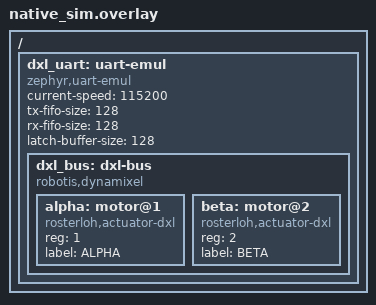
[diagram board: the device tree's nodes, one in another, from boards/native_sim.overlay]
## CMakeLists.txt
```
# Copyright (c) 2024 Richard Osterloh <richard.osterloh@gmail.com>
# SPDX-License-Identifier: Apache-2.0
cmake_minimum_required(VERSION 3.20.0)

find_package(Zephyr REQUIRED HINTS $ENV{ZEPHYR_BASE})
project(test_dynamixel)

target_sources(app PRIVATE
    src/main.c
    src/fake_servo.c
    src/fake_bus.c
    src/test_protocol.c
    src/test_tables.c
    src/test_motors.c
    src/test_sync.c
    src/test_bulk.c
)

zephyr_include_directories(./src)
zephyr_include_directories(${ZEPHYR_DRIVERS_REPO_ROOT}/drivers/dynamixel)
```

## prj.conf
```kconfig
# tests/drivers/dynamixel/prj.conf
CONFIG_LOG=y
CONFIG_ZTEST=y
CONFIG_SERIAL=y
CONFIG_UART_INTERRUPT_DRIVEN=y
CONFIG_EMUL=y
CONFIG_UART_EMUL=y
CONFIG_DYNAMIXEL=y
CONFIG_DYNAMIXEL_LOG_LEVEL_DBG=y
# Higher tick resolution so that µs-level timeouts (rxwait_to, packet_timer,
# SYNC/BULK slot gaps) quantise accurately on native_sim's 1 MHz HW clock.
CONFIG_SYS_CLOCK_TICKS_PER_SEC=10000
```

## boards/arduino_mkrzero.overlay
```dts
/*
 * Copyright (c) 2024 Richard Osterloh <richard.osterloh@gmail.com>
 *
 * SPDX-License-Identifier: Apache-2.0
 */
 
 &sercom5 {
	status = "okay";
	current-speed = <115200>;

	dynamixel0 {
		status = "okay";
		compatible = "robotis,dynamixel";
		tx-en-gpios = <&arduino_mkr_header 21 GPIO_ACTIVE_LOW>; // A6

		test_motor {
			id = <1>;
			label = "TEST";
		};
	};
};
```

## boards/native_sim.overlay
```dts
/*
 * Copyright (c) 2026 Richard Osterloh <richard.osterloh@gmail.com>
 *
 * SPDX-License-Identifier: Apache-2.0
 */

/ {
	dxl_uart: uart-emul {
		compatible = "zephyr,uart-emul";
		current-speed = <115200>;
		tx-fifo-size = <128>;
		rx-fifo-size = <128>;
		latch-buffer-size = <128>;
		status = "okay";

		dxl_bus: dxl-bus {
			status = "okay";
			compatible = "robotis,dynamixel";
			#address-cells = <1>;
			#size-cells = <0>;

			alpha: motor@1 {
				compatible = "rosterloh,actuator-dxl";
				reg = <1>;
				label = "ALPHA";
			};

			beta: motor@2 {
				compatible = "rosterloh,actuator-dxl";
				reg = <2>;
				label = "BETA";
			};
		};
	};
};
```

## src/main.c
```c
/*
 * Copyright (c) 2026 Richard Osterloh <richard.osterloh@gmail.com>
 *
 * SPDX-License-Identifier: Apache-2.0
 */

#include <zephyr/ztest.h>

ZTEST_SUITE(dynamixel_tables, NULL, NULL, NULL, NULL, NULL);
ZTEST_SUITE(dynamixel_motors, NULL, NULL, NULL, NULL, NULL);
```

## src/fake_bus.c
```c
/*
 * Copyright (c) 2026 Richard Osterloh <richard.osterloh@gmail.com>
 *
 * SPDX-License-Identifier: Apache-2.0
 */

#include "fake_bus.h"

#include <string.h>
#include <zephyr/sys/byteorder.h>
#include <zephyr/drivers/serial/uart_emul.h>

#include <zephyr/logging/log.h>
LOG_MODULE_REGISTER(fake_bus, LOG_LEVEL_INF);

#define DXL_BROADCAST_ID 0xFE
#define INST_SYNC_READ   0x82
#define INST_BULK_READ   0x92
#define INST_SYNC_WRITE  0x83
#define INST_BULK_WRITE  0x93

/* Forward decl — implemented later in the SYNC/BULK tasks. */
static void inject_work_fn(struct k_work *w);

struct fake_servo *fake_bus_get(struct fake_bus *bus, uint8_t id)
{
	for (size_t i = 0; i < bus->n; i++) {
		if (bus->srv[i].id == id) {
			return &bus->srv[i];
		}
	}
	return NULL;
}

/* SYNC_WRITE param layout (after instruction byte):
 *   addr_le16 ‖ data_len_le16 ‖ {id, data[L]} × N
 * pkt[8..9]   = addr,
 * pkt[10..11] = data_len,
 * pkt[12..]   = repeating (id, data[L]).
 */
static void dispatch_sync_write(struct fake_bus *bus, const uint8_t *pkt, size_t len)
{
	if (len < 14) {
		return; /* need at least addr + len + crc */
	}
	uint16_t addr = sys_get_le16(&pkt[8]);
	uint16_t data_len = sys_get_le16(&pkt[10]);
	const uint8_t *p = &pkt[12];
	const uint8_t *end = &pkt[len - 2]; /* before CRC */

	while (p + 1 + data_len <= end) {
		uint8_t id = p[0];
		struct fake_servo *s = fake_bus_get(bus, id);
		if (s != NULL && addr + data_len <= FAKE_SERVO_RAM_SIZE) {
			memcpy(&s->control_ram[addr], &p[1], data_len);
			s->last_addr = addr;
			s->last_length = data_len;
		}
		p += 1 + data_len;
	}
}

/* BULK_WRITE param layout (after instruction byte):
 *   {id, addr_le16, len_le16, data[L]} × N
 * pkt[8..]    = repeating per-entry blocks.
 */
static void dispatch_bulk_write(struct fake_bus *bus, const uint8_t *pkt, size_t len)
{
	if (len < 10) {
		return;
	}
	const uint8_t *p = &pkt[8];
	const uint8_t *end = &pkt[len - 2]; /* before CRC */

	while (p + 5 <= end) {
		uint8_t id = p[0];
		uint16_t addr = sys_get_le16(&p[1]);
		uint16_t data_len = sys_get_le16(&p[3]);
		if (p + 5 + data_len > end) {
			break;
		}
		struct fake_servo *s = fake_bus_get(bus, id);
		if (s != NULL && addr + data_len <= FAKE_SERVO_RAM_SIZE) {
			memcpy(&s->control_ram[addr], &p[5], data_len);
			s->last_addr = addr;
			s->last_length = data_len;
		}
		p += 5 + data_len;
	}
}

/* Helper: directly emit a status reply for one fake. Mirrors fake_servo's
 * own send_status path but is reachable from outside the per-fake module.
 *
 * Implementation: reuses fake_servo_handle_packet by feeding it a synthetic
 * READ instruction packet for that servo. This way fake_servo's existing
 * drop_response / corrupt_crc / error_byte knobs apply automatically.
 */
static void emit_status_via_synthetic_read(struct fake_servo *s, uint16_t addr, uint16_t length)
{
	uint8_t synth[14];
	uint16_t length_field = 1 /* inst */ + 4 /* params */ + 2 /* crc */;

	synth[0] = 0xFF;
	synth[1] = 0xFF;
	synth[2] = 0xFD;
	synth[3] = 0x00;
	synth[4] = s->id;
	sys_put_le16(length_field, &synth[5]);
	synth[7] = 0x02; /* INST_READ */
	sys_put_le16(addr, &synth[8]);
	sys_put_le16(length, &synth[10]);
	/* CRC bytes left zero — fake_servo_handle_packet doesn't validate the
	 * inbound CRC, only header + instruction. The bytes at &synth[12] are
	 * "CRC", but handle_packet treats pkt[8..11] as params and ignores
	 * trailing bytes for READ.
	 */

	fake_servo_handle_packet(s, synth, sizeof(synth));
}

/* BULK_READ param layout (after instruction byte):
 *   {id, addr_le16, len_le16} × N
 */
static void dispatch_bulk_read(struct fake_bus *bus, const uint8_t *pkt, size_t len)
{
	if (len < 10) {
		return;
	}
	const uint8_t *p = &pkt[8];
	const uint8_t *end = &pkt[len - 2];
	size_t entries = 0;

	bus->pending_active = true;
	bus->pending_is_bulk = true;
	bus->pending_idx = 0;
	bus->prev_dropped = false;

	while (p + 5 <= end && entries < FAKE_BUS_MAX_SERVOS) {
		bus->pending_ids[entries] = p[0];
		bus->pending_addrs[entries] = sys_get_le16(&p[1]);
		bus->pending_lens[entries] = sys_get_le16(&p[3]);
		entries++;
		p += 5;
	}

	if (entries == 0) {
		bus->pending_active = false;
		return;
	}

	bus->pending_n = entries;
	k_work_reschedule(&bus->inject_work, K_NO_WAIT);
}

/* SYNC_READ param layout (after instruction byte):
 *   addr_le16 ‖ data_len_le16 ‖ id[0..n-1]
 */
static void dispatch_sync_read(struct fake_bus *bus, const uint8_t *pkt, size_t len)
{
	if (len < 14) {
		return;
	}
	uint16_t addr = sys_get_le16(&pkt[8]);
	uint16_t data_len = sys_get_le16(&pkt[10]);
	const uint8_t *id_list = &pkt[12];
	const uint8_t *end = &pkt[len - 2]; /* before CRC */
	size_t n = (size_t)(end - id_list);

	if (n == 0 || n > FAKE_BUS_MAX_SERVOS) {
		return;
	}

	bus->pending_active = true;
	bus->pending_is_bulk = false;
	bus->pending_addr_uniform = addr;
	bus->pending_len_uniform = data_len;
	bus->pending_n = n;
	bus->pending_idx = 0;
	bus->prev_dropped = false;
	for (size_t i = 0; i < n; i++) {
		bus->pending_ids[i] = id_list[i];
	}

	/* Kick off the first injection at K_NO_WAIT so it runs after the test
	 * thread has returned from dxl_sync_read_*'s TX call and entered the
	 * first k_sem_take. K_NO_WAIT is fine because the work item runs on the
	 * system workqueue which can't pre-empt the test thread mid-sem-take.
	 */
	k_work_reschedule(&bus->inject_work, K_NO_WAIT);
}

static void dispatch_single_target(struct fake_bus *bus, const uint8_t *pkt, size_t len)
{
	uint8_t target_id = pkt[4];

	if (target_id == DXL_BROADCAST_ID) {
		/* Broadcast PING/READ/WRITE — out of scope for Task 4; later tasks handle
		 * SYNC/BULK broadcasts which carry their own targeting in params.
		 */
		return;
	}

	struct fake_servo *s = fake_bus_get(bus, target_id);
	if (s != NULL) {
		fake_servo_handle_packet(s, pkt, len);
	}
}

static void tx_data_ready_cb(const struct device *dev, size_t size, void *user_data)
{
	struct fake_bus *bus = user_data;
	uint8_t buf[FAKE_SERVO_LAST_TX_SIZE * 2]; /* large enough for any single-shot frame */
	uint32_t got;

	if (size > sizeof(buf)) {
		size = sizeof(buf);
	}
	got = uart_emul_get_tx_data(dev, buf, size);
	if (got < 10) {
		return; /* malformed: too short for header+id+len+inst+crc */
	}

	/* Capture in every fake's last_tx/last_instruction so test code can assert
	 * on them regardless of which servo was addressed.
	 */
	for (size_t i = 0; i < bus->n; i++) {
		struct fake_servo *s = &bus->srv[i];
		s->last_tx_len = MIN(got, sizeof(s->last_tx));
		memcpy(s->last_tx, buf, s->last_tx_len);
		s->last_instruction = buf[7];
	}

	uint8_t inst = buf[7];

	switch (inst) {
	case INST_SYNC_READ:
		dispatch_sync_read(bus, buf, got);
		break;
	case INST_SYNC_WRITE:
		dispatch_sync_write(bus, buf, got);
		break;
	case INST_BULK_READ:
		dispatch_bulk_read(bus, buf, got);
		break;
	case INST_BULK_WRITE:
		dispatch_bulk_write(bus, buf, got);
		break;
	default:
		dispatch_single_target(bus, buf, got);
		break;
	}
}

void fake_bus_init(struct fake_bus *bus, const uint8_t ids[], size_t n)
{
	memset(bus, 0, sizeof(*bus));
	bus->n = MIN(n, (size_t)FAKE_BUS_MAX_SERVOS);
	for (size_t i = 0; i < bus->n; i++) {
		fake_servo_init(&bus->srv[i], ids[i]);
	}
	k_work_init_delayable(&bus->inject_work, inject_work_fn);
}

void fake_bus_attach(struct fake_bus *bus, const struct device *uart)
{
	bus->uart = uart;
	for (size_t i = 0; i < bus->n; i++) {
		bus->srv[i].uart = uart;
	}
	uart_emul_callback_tx_data_ready_set(uart, tx_data_ready_cb, bus);
}

void fake_bus_set_u8(struct fake_bus *bus, uint8_t id, uint16_t addr, uint8_t value)
{
	struct fake_servo *s = fake_bus_get(bus, id);
	if (s != NULL) {
		fake_servo_set_u8(s, addr, value);
	}
}

void fake_bus_set_u16(struct fake_bus *bus, uint8_t id, uint16_t addr, uint16_t value)
{
	struct fake_servo *s = fake_bus_get(bus, id);
	if (s != NULL) {
		fake_servo_set_u16(s, addr, value);
	}
}

void fake_bus_set_u32(struct fake_bus *bus, uint8_t id, uint16_t addr, uint32_t value)
{
	struct fake_servo *s = fake_bus_get(bus, id);
	if (s != NULL) {
		fake_servo_set_u32(s, addr, value);
	}
}

static void inject_work_fn(struct k_work *w)
{
	struct k_work_delayable *dw = k_work_delayable_from_work(w);
	struct fake_bus *bus = CONTAINER_OF(dw, struct fake_bus, inject_work);

	if (!bus->pending_active || bus->pending_idx >= bus->pending_n) {
		bus->pending_active = false;
		return;
	}

	uint8_t id = bus->pending_ids[bus->pending_idx];
	uint16_t addr = bus->pending_is_bulk ? bus->pending_addrs[bus->pending_idx]
					     : bus->pending_addr_uniform;
	uint16_t length = bus->pending_is_bulk ? bus->pending_lens[bus->pending_idx]
					       : bus->pending_len_uniform;

	struct fake_servo *s = fake_bus_get(bus, id);
	bool dropped = (s == NULL) || s->drop_response;

	if (s != NULL) {
		emit_status_via_synthetic_read(s, addr, length);
	}

	bus->pending_idx++;
	bus->prev_dropped = dropped;

	if (bus->pending_idx < bus->pending_n) {
		uint32_t gap = bus->prev_dropped ? FAKE_BUS_DROP_GAP_US : FAKE_BUS_SLOT_GAP_US;
		k_work_reschedule(&bus->inject_work, K_USEC(gap));
	} else {
		bus->pending_active = false;
	}
}
```

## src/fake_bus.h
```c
/*
 * Copyright (c) 2026 Richard Osterloh <richard.osterloh@gmail.com>
 *
 * SPDX-License-Identifier: Apache-2.0
 */

#ifndef TEST_FAKE_BUS_H_
#define TEST_FAKE_BUS_H_

#include <stdbool.h>
#include <stdint.h>
#include <stddef.h>
#include <zephyr/device.h>
#include <zephyr/kernel.h>
#include <drivers/dynamixel.h>

#include "fake_servo.h"

#define FAKE_BUS_MAX_SERVOS 4

/* Inter-packet timing for sync/bulk read injection.
 *
 * SLOT_GAP_US: gap between consecutive injected status packets in the
 *   happy-path case. Must exceed the driver's inter-frame packet_timeout
 *   (~1003 us at 115200 baud) so the packet_timer fires between frames.
 *
 * DROP_GAP_US: gap when the previous slot was a drop. Must satisfy
 *   (rxwait_to - SLOT_GAP) < DROP_GAP < (2*rxwait_to - packet_timer):
 *   - lower bound prevents the next inject arriving while the dropped slot
 *     k_sem_take is still active (would corrupt expected_id matching);
 *   - upper bound ensures the next inject arrives inside the next slot's
 *     k_sem_take window with margin for the inter-frame packet_timer.
 *   With rxwait_to = 10 ms, the safe range is roughly 7..14 ms; 12 ms gives
 *   ~3 ms margin on both sides.
 */
#define FAKE_BUS_SLOT_GAP_US 5000U
#define FAKE_BUS_DROP_GAP_US 12000U

struct fake_bus {
	struct fake_servo srv[FAKE_BUS_MAX_SERVOS];
	size_t n;
	const struct device *uart;

	/* Pending response queue (set by tx dispatcher when SYNC/BULK_READ seen). */
	bool pending_active;
	bool pending_is_bulk;
	uint8_t pending_ids[FAKE_BUS_MAX_SERVOS];
	uint16_t pending_addr_uniform;               /* sync-read only */
	uint16_t pending_len_uniform;                /* sync-read only */
	uint16_t pending_addrs[FAKE_BUS_MAX_SERVOS]; /* bulk-read only */
	uint16_t pending_lens[FAKE_BUS_MAX_SERVOS];  /* bulk-read only */
	size_t pending_n;
	size_t pending_idx;
	bool prev_dropped;

	struct k_work_delayable inject_work;
};

void fake_bus_init(struct fake_bus *bus, const uint8_t ids[], size_t n);
void fake_bus_attach(struct fake_bus *bus, const struct device *uart);

struct fake_servo *fake_bus_get(struct fake_bus *bus, uint8_t id);

/* Convenience wrappers for pre-loading register state per servo by id. */
void fake_bus_set_u8(struct fake_bus *bus, uint8_t id, uint16_t addr, uint8_t value);
void fake_bus_set_u16(struct fake_bus *bus, uint8_t id, uint16_t addr, uint16_t value);
void fake_bus_set_u32(struct fake_bus *bus, uint8_t id, uint16_t addr, uint32_t value);

#endif /* TEST_FAKE_BUS_H_ */
```

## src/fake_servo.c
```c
/*
 * Copyright (c) 2026 Richard Osterloh <richard.osterloh@gmail.com>
 *
 * SPDX-License-Identifier: Apache-2.0
 */

#include "fake_servo.h"

#include <string.h>
#include <zephyr/sys/byteorder.h>
#include <zephyr/sys/crc.h>
#include <zephyr/drivers/serial/uart_emul.h>

#include <zephyr/logging/log.h>
LOG_MODULE_REGISTER(fake_servo, LOG_LEVEL_INF);

#define DXL_HDR0 0xFF
#define DXL_HDR1 0xFF
#define DXL_HDR2 0xFD
#define DXL_RSV  0x00

#define INST_PING   0x01
#define INST_READ   0x02
#define INST_WRITE  0x03
#define INST_REBOOT 0x08
#define INST_STATUS 0x55

#define CRC_POLY 0x8005
#define CRC_SEED 0x0000

/* Protocol 2.0 byte stuffing from offset 8: an extra 0xFD follows every FF FF FD. */
static bool stuff_point(const uint8_t *buf, size_t i)
{
	return i >= 10 && buf[i - 2] == 0xFF && buf[i - 1] == 0xFF && buf[i] == 0xFD;
}

/* Stuff buf[8..len) in place; returns the new length. */
static size_t stuff(uint8_t *buf, size_t len, size_t cap)
{
	for (size_t i = 8; i < len; i++) {
		if (stuff_point(buf, i) && len < cap) {
			memmove(&buf[i + 2], &buf[i + 1], len - i - 1);
			buf[++i] = 0xFD;
			len++;
		}
	}
	return len;
}

/* Undo stuff() on buf[8..len); returns the new length. */
static size_t unstuff(uint8_t *buf, size_t len)
{
	size_t out = 8;

	for (size_t i = 8; i < len; i++) {
		if (stuff_point(buf, i - 1) && buf[i] == 0xFD) {
			continue;
		}
		buf[out++] = buf[i];
	}
	return out;
}

static void send_status(struct fake_servo *s, uint8_t error, const uint8_t *params,
			uint16_t params_len)
{
	uint8_t buf[FAKE_SERVO_STATUS_BUF_SIZE];
	uint16_t length = params_len + 1 /* error */ + 2 /* crc */ + 1 /* instruction */;
	uint16_t total = length + 7;
	uint16_t crc;

	if (s->drop_response) {
		return;
	}

	buf[0] = DXL_HDR0;
	buf[1] = DXL_HDR1;
	buf[2] = DXL_HDR2;
	buf[3] = DXL_RSV;
	buf[4] = s->id;
	sys_put_le16(length, &buf[5]);
	buf[7] = INST_STATUS;
	buf[8] = error;
	if (params_len > 0) {
		memcpy(&buf[9], params, params_len);
	}
	total = stuff(buf, total - 2, sizeof(buf) - 2) + 2;
	sys_put_le16(total - 7, &buf[5]);
	crc = crc16(CRC_POLY, CRC_SEED, buf, total - 2);
	if (s->corrupt_crc) {
		crc ^= 0x0001;
	}
	sys_put_le16(crc, &buf[total - 2]);
	if (s->corrupt_length) {
		sys_put_le16(0xFFFF, &buf[5]);
	}

	uart_emul_put_rx_data(s->uart, buf, total);
}

void fake_servo_handle_packet(struct fake_servo *s, const uint8_t *pkt, size_t len)
{
	uint8_t id;
	uint16_t length;
	uint8_t inst;

	if (len < 10) {
		return;
	}
	if (pkt[0] != DXL_HDR0 || pkt[1] != DXL_HDR1 || pkt[2] != DXL_HDR2) {
		return;
	}
	/* Capture the wire bytes for assertions, then parse the unstuffed frame. */
	s->last_tx_len = MIN(len, sizeof(s->last_tx));
	memcpy(s->last_tx, pkt, s->last_tx_len);

	uint8_t raw[FAKE_SERVO_LAST_TX_SIZE];

	memcpy(raw, pkt, s->last_tx_len);
	len = unstuff(raw, s->last_tx_len - 2) + 2;
	pkt = raw;

	id = pkt[4];
	length = len - 7;
	inst = pkt[7];
	s->last_instruction = inst;

	if (id != s->id && !s->answer_any_id) {
		return; /* not addressed to this servo */
	}

	switch (inst) {
	case INST_PING:
		send_status(s, s->error_byte, NULL, 0);
		break;
	case INST_READ: {
		if (len < 14) {
			return; /* malformed: READ needs 4 param bytes */
		}
		uint16_t addr = sys_get_le16(&pkt[8]);
		uint16_t rlen = sys_get_le16(&pkt[10]);
		s->last_addr = addr;
		s->last_length = rlen;
		if (addr + rlen <= FAKE_SERVO_RAM_SIZE) {
			send_status(s, s->error_byte, &s->control_ram[addr], rlen);
		} else {
			send_status(s, s->error_byte, NULL, 0);
		}
		break;
	}
	case INST_WRITE: {
		if (len < 12) {
			return; /* malformed: WRITE needs at least 2 addr bytes */
		}
		uint16_t addr = sys_get_le16(&pkt[8]);
		uint16_t params = length - 5; /* length covers ic + 2 addr + params + 2 crc */
		s->last_addr = addr;
		s->last_length = params;
		if (addr + params <= FAKE_SERVO_RAM_SIZE) {
			memcpy(&s->control_ram[addr], &pkt[10], params);
		}
		send_status(s, s->error_byte, NULL, 0);
		break;
	}
	case INST_REBOOT:
		send_status(s, s->error_byte, NULL, 0);
		break;
	default:
		break;
	}
}

static void tx_data_ready_cb(const struct device *dev, size_t size, void *user_data)
{
	struct fake_servo *s = user_data;
	uint8_t buf[FAKE_SERVO_LAST_TX_SIZE];
	uint32_t got;

	if (size > sizeof(buf)) {
		size = sizeof(buf);
	}
	got = uart_emul_get_tx_data(dev, buf, size);
	if (got == 0) {
		return;
	}
	fake_servo_handle_packet(s, buf, got);
}

void fake_servo_init(struct fake_servo *s, uint8_t id)
{
	memset(s, 0, sizeof(*s));
	s->id = id;
}

void fake_servo_attach(struct fake_servo *s, const struct device *uart)
{
	s->uart = uart;
	uart_emul_callback_tx_data_ready_set(uart, tx_data_ready_cb, s);
}

void fake_servo_set_u8(struct fake_servo *s, uint16_t addr, uint8_t value)
{
	s->control_ram[addr] = value;
}

void fake_servo_set_u16(struct fake_servo *s, uint16_t addr, uint16_t value)
{
	sys_put_le16(value, &s->control_ram[addr]);
}

void fake_servo_set_u32(struct fake_servo *s, uint16_t addr, uint32_t value)
{
	sys_put_le32(value, &s->control_ram[addr]);
}

uint8_t fake_servo_get_u8(struct fake_servo *s, uint16_t addr)
{
	return s->control_ram[addr];
}

uint16_t fake_servo_get_u16(struct fake_servo *s, uint16_t addr)
{
	return sys_get_le16(&s->control_ram[addr]);
}

uint32_t fake_servo_get_u32(struct fake_servo *s, uint16_t addr)
{
	return sys_get_le32(&s->control_ram[addr]);
}
```

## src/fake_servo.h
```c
/*
 * Copyright (c) 2026 Richard Osterloh <richard.osterloh@gmail.com>
 *
 * SPDX-License-Identifier: Apache-2.0
 */

#ifndef TEST_FAKE_SERVO_H_
#define TEST_FAKE_SERVO_H_

#include <stdbool.h>
#include <stdint.h>
#include <stddef.h>
#include <zephyr/device.h>

#define FAKE_SERVO_RAM_SIZE        256
#define FAKE_SERVO_LAST_TX_SIZE    64
/* Status reply uses params_len (<= RAM size) + 11 bytes of framing, plus room
 * for byte stuffing.
 */
#define FAKE_SERVO_STATUS_BUF_SIZE (FAKE_SERVO_RAM_SIZE + 11 + 16)

struct fake_servo {
	uint8_t id;
	uint8_t control_ram[FAKE_SERVO_RAM_SIZE];

	/* Behaviour knobs */
	bool drop_response;
	bool corrupt_crc;
	bool corrupt_length; /* claim a 0xFFFF length field, CRC left as computed */
	uint8_t error_byte;
	bool answer_any_id; /* if true, reply regardless of addressed id (with own id) */

	/* Capture of the most recent request */
	uint8_t last_tx[FAKE_SERVO_LAST_TX_SIZE];
	size_t last_tx_len;
	uint8_t last_instruction;
	uint16_t last_addr;
	uint16_t last_length;

	/* Internal: bound UART device for response injection */
	const struct device *uart;
};

void fake_servo_init(struct fake_servo *s, uint8_t id);
void fake_servo_attach(struct fake_servo *s, const struct device *uart);

/* Pre-load a value into the fake servo's RAM at a given address.
 * Used to set up READ test cases.
 */
void fake_servo_set_u8(struct fake_servo *s, uint16_t addr, uint8_t value);
void fake_servo_set_u16(struct fake_servo *s, uint16_t addr, uint16_t value);
void fake_servo_set_u32(struct fake_servo *s, uint16_t addr, uint32_t value);

uint8_t fake_servo_get_u8(struct fake_servo *s, uint16_t addr);
uint16_t fake_servo_get_u16(struct fake_servo *s, uint16_t addr);
uint32_t fake_servo_get_u32(struct fake_servo *s, uint16_t addr);

/* Process one received instruction packet. The fake reacts (sends status if
 * applicable) and updates last_tx / last_instruction / last_addr / last_length.
 * Used by fake_bus to dispatch packets to the right servo.
 */
void fake_servo_handle_packet(struct fake_servo *s, const uint8_t *pkt, size_t len);

#endif /* TEST_FAKE_SERVO_H_ */
```

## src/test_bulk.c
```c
/*
 * Copyright (c) 2026 Richard Osterloh <richard.osterloh@gmail.com>
 *
 * SPDX-License-Identifier: Apache-2.0
 */

#include <zephyr/ztest.h>
#include <zephyr/device.h>
#include <zephyr/devicetree.h>
#include <drivers/dynamixel.h>

#include "fake_bus.h"

#define DXL_BUS_NODE   DT_NODELABEL(dxl_bus)
#define DXL_UART_NODE  DT_PARENT(DXL_BUS_NODE)
#define DXL_IFACE_NAME DEVICE_DT_NAME(DXL_BUS_NODE)

#define FAKE_BUS_RXWAIT_TO_US 10000U

static const struct device *uart_dev = DEVICE_DT_GET(DXL_UART_NODE);

static struct fake_bus bus;
static int iface;

static void bulk_before_each(void *fixture)
{
	ARG_UNUSED(fixture);

	const uint8_t ids[] = {1, 2, 3, 4};
	struct dxl_iface_param p = {
		.rx_timeout = FAKE_BUS_RXWAIT_TO_US,
		.serial = {.baud = 115200, .parity = UART_CFG_PARITY_NONE},
	};

	fake_bus_init(&bus, ids, ARRAY_SIZE(ids));
	fake_bus_attach(&bus, uart_dev);

	iface = dxl_iface_get_by_name(DXL_IFACE_NAME);
	zassert_true(iface >= 0, "iface lookup failed: %d", iface);
	zassert_ok(dxl_init(iface, p), "dxl_init failed");
}

static void bulk_after_each(void *fixture)
{
	ARG_UNUSED(fixture);
	dxl_disable(iface);
}

ZTEST_SUITE(dynamixel_bulk, NULL, NULL, bulk_before_each, bulk_after_each, NULL);

ZTEST(dynamixel_bulk, test_bulk_read_happy_mixed_widths)
{
	const struct dxl_bulk_read_entry req[] = {
		{.id = 1, .item = TORQUE_ENABLE},    /* width 1, addr 64 */
		{.id = 2, .item = GOAL_PWM},         /* width 2, addr 100 */
		{.id = 3, .item = PRESENT_POSITION}, /* width 4, addr 132 */
		{.id = 4, .item = TORQUE_ENABLE},    /* width 1 */
	};
	uint32_t vals[4] = {0};
	int errs[4] = {-1, -1, -1, -1};

	fake_bus_set_u8(&bus, 1, 64, 1);
	fake_bus_set_u16(&bus, 2, 100, 0xCAFE);
	fake_bus_set_u32(&bus, 3, 132, 0xDEADBEEF);
	fake_bus_set_u8(&bus, 4, 64, 0);

	zassert_ok(dxl_bulk_read(iface, req, vals, errs, ARRAY_SIZE(req)), "bulk_read failed");

	zassert_equal(vals[0], 1, "vals[0]");
	zassert_equal(vals[1], 0xCAFE, "vals[1]");
	zassert_equal(vals[2], 0xDEADBEEF, "vals[2]");
	zassert_equal(vals[3], 0, "vals[3]");
	zassert_equal(errs[0], 0, "errs[0]");
	zassert_equal(errs[1], 0, "errs[1]");
	zassert_equal(errs[2], 0, "errs[2]");
	zassert_equal(errs[3], 0, "errs[3]");
}

ZTEST(dynamixel_bulk, test_bulk_read_validation_einval)
{
	const struct dxl_bulk_read_entry req[] = {
		{.id = 1, .item = PRESENT_POSITION},
		{.id = 2, .item = PRESENT_POSITION},
	};
	const struct dxl_bulk_read_entry bad_req[] = {
		{.id = 1, .item = (enum dxl_control)9999},
	};
	uint32_t vals[2] = {0};

	zassert_equal(dxl_bulk_read(iface, req, vals, NULL, 0), -EINVAL, "n=0");
	zassert_equal(dxl_bulk_read(iface, NULL, vals, NULL, 2), -EINVAL, "NULL req");
	zassert_equal(dxl_bulk_read(iface, req, NULL, NULL, 2), -EINVAL, "NULL vals");
	zassert_equal(dxl_bulk_read(iface, bad_req, vals, NULL, 1), -EINVAL, "bad item");
}

ZTEST(dynamixel_bulk, test_bulk_read_enospc_when_oversized)
{
	struct dxl_bulk_read_entry req[64];
	uint32_t vals[64];
	for (size_t i = 0; i < ARRAY_SIZE(req); i++) {
		req[i].id = (uint8_t)((i % 250) + 1);
		req[i].item = PRESENT_POSITION;
		vals[i] = 0;
	}

	/* BULK_READ packet is 10 + N*5 bytes. For N=64 -> 330 > 256 default. */
	zassert_equal(dxl_bulk_read(iface, req, vals, NULL, 64), -ENOSPC,
		      "oversized BULK_READ must return -ENOSPC");
}

ZTEST(dynamixel_bulk, test_bulk_write_happy_mixed_widths)
{
	const struct dxl_bulk_write_entry req[] = {
		{.id = 1, .item = TORQUE_ENABLE, .value = 1},
		{.id = 2, .item = GOAL_PWM, .value = 0x0BEE},
		{.id = 3, .item = GOAL_POSITION, .value = 0xDEADBEEF},
		{.id = 4, .item = TORQUE_ENABLE, .value = 0},
	};

	zassert_ok(dxl_bulk_write(iface, req, ARRAY_SIZE(req)), "bulk_write failed");

	/* BULK_WRITE is fire-and-forget at the protocol layer. The emulated
	 * UART drains TX bytes through a worker thread, so we yield long
	 * enough for the bytes to reach the fake_bus dispatcher before
	 * checking register state.
	 */
	k_sleep(K_MSEC(2));

	zassert_equal(fake_servo_get_u8(fake_bus_get(&bus, 1), 64), 1, "id 1");
	zassert_equal(fake_servo_get_u16(fake_bus_get(&bus, 2), 100), 0x0BEE, "id 2");
	zassert_equal(fake_servo_get_u32(fake_bus_get(&bus, 3), 116), 0xDEADBEEF, "id 3");
	zassert_equal(fake_servo_get_u8(fake_bus_get(&bus, 4), 64), 0, "id 4");
}

ZTEST(dynamixel_bulk, test_bulk_write_validation_einval)
{
	const struct dxl_bulk_write_entry req[] = {
		{.id = 1, .item = GOAL_POSITION, .value = 0},
	};
	const struct dxl_bulk_write_entry bad_req[] = {
		{.id = 1, .item = (enum dxl_control)9999, .value = 0},
	};

	zassert_equal(dxl_bulk_write(iface, req, 0), -EINVAL, "n=0");
	zassert_equal(dxl_bulk_write(iface, NULL, 1), -EINVAL, "NULL req");
	zassert_equal(dxl_bulk_write(iface, bad_req, 1), -EINVAL, "bad item");
}

ZTEST(dynamixel_bulk, test_bulk_write_enospc_when_oversized)
{
	struct dxl_bulk_write_entry req[32];
	for (size_t i = 0; i < ARRAY_SIZE(req); i++) {
		req[i].id = (uint8_t)((i % 250) + 1);
		req[i].item = GOAL_POSITION; /* width 4 */
		req[i].value = 0;
	}

	/* BULK_WRITE packet is 10 + N*(5+L). For N=32, L=4 -> 298 > 256 default. */
	zassert_equal(dxl_bulk_write(iface, req, 32), -ENOSPC,
		      "oversized BULK_WRITE must return -ENOSPC");
}
```

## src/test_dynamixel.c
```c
/*
 * Copyright (c) 2024 Richard Osterloh <richard.osterloh@gmail.com>
 *
 * SPDX-License-Identifier: Apache-2.0
 */

#include "test_dynamixel.h"

#include <zephyr/logging/log.h>
LOG_MODULE_REGISTER(dxl_test, LOG_LEVEL_INF);

static uint8_t dxl_iface;

uint8_t test_get_dxl_iface(void)
{
	return dxl_iface;
}

static struct dxl_iface_param dxl_param = {
	.rx_timeout = DXL_TEST_RESPONSE_TO,
	.serial =
		{
			.baud = DXL_TEST_BAUDRATE_LOW,
			.parity = DXL_TEST_PARITY,
		},
};

/*
 * This test performed on hardware requires two UART controllers
 * on the board (with RX/TX lines connected crosswise).
 * The exact mapping is not required, we assume that both controllers
 * have similar capabilities and use the instance with index 0
 * as interface for the client.
 */
#if DT_NODE_EXISTS(DT_INST(0, robotis_dynamixel))
static const char iface_name[] = {DEVICE_DT_NAME(DT_INST(0, robotis_dynamixel))};
#else
static const char iface_name[] = "";
#endif

void test_setup_iface(void)
{
	int err;

	dxl_iface = dxl_iface_get_by_name(iface_name);
	dxl_param.serial.baud = DXL_TEST_BAUDRATE_LOW;
	dxl_param.serial.parity = UART_CFG_PARITY_NONE;

	err = dxl_init(dxl_iface, dxl_param);
	zassert_equal(err, 0, "Failed to configure DYNAMIXEL interface");
}

void test_disable(void)
{
	int err;

	err = dxl_disable(dxl_iface);
	zassert_equal(err, 0, "Failed to disable DYNAMIXEL interface");
}
```

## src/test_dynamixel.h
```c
/*
 * Copyright (c) 2024 Richard Osterloh <richard.osterloh@gmail.com>
 *
 * SPDX-License-Identifier: Apache-2.0
 */

#ifndef __TEST_DYNAMIXEL_H__
#define __TEST_DYNAMIXEL_H__

#include <zephyr/drivers/uart.h>
#include <zephyr/ztest.h>
#include <drivers/dynamixel.h>

#define DXL_TEST_BAUDRATE_LOW 57600
#define DXL_TEST_BAUDRATE_HIGH 115200
#define DXL_TEST_PARITY UART_CFG_PARITY_NONE
#define DXL_TEST_RESPONSE_TO 5000

/*
 * Integration platform for this test is MKR Zero.
 * The board must be prepared accordingly:
 * SERCOM5(PB23)-RX <-> SERCOM4(PB10)-TX pins and
 * SERCOM5(PB22)-TX <-> SERCOM4(PB11)-RX pins have to be connected.
 */

uint8_t test_get_dxl_iface(void);

void test_setup_iface(void);
void test_disable(void);

#endif /* __TEST_DYNAMIXEL_H__ */
```

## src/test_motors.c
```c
/*
 * Copyright (c) 2026 Richard Osterloh <richard.osterloh@gmail.com>
 *
 * SPDX-License-Identifier: Apache-2.0
 */

#include <string.h>
#include <zephyr/ztest.h>
#include <drivers/dynamixel.h>

ZTEST(dynamixel_motors, test_motor_count)
{
	zassert_equal(dxl_motor_count(), 2, "two motors in overlay");
}

ZTEST(dynamixel_motors, test_lookup_by_label)
{
	const struct dxl_motor *m = dxl_motor_get_by_label("ALPHA");

	zassert_not_null(m, "ALPHA must be found");
	zassert_equal(m->id, 1, "ALPHA id");

	m = dxl_motor_get_by_label("BETA");
	zassert_not_null(m, "BETA must be found");
	zassert_equal(m->id, 2, "BETA id");
}

ZTEST(dynamixel_motors, test_lookup_missing_label)
{
	zassert_is_null(dxl_motor_get_by_label("nope"), "missing label returns NULL");
}

ZTEST(dynamixel_motors, test_iface_consistent)
{
	const struct dxl_motor *m0 = dxl_motor_get(0);
	const struct dxl_motor *m1 = dxl_motor_get(1);

	zassert_not_null(m0, "motor 0");
	zassert_not_null(m1, "motor 1");
	zassert_equal(m0->iface, m1->iface, "both motors on same iface");
}
```

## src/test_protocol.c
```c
/*
 * Copyright (c) 2026 Richard Osterloh <richard.osterloh@gmail.com>
 *
 * SPDX-License-Identifier: Apache-2.0
 *
 * Phase 1 BUG-PINNING TESTS. These intentionally assert current
 * (buggy) behavior so they are green now. Phase 3 of the cleanup
 * flips them.
 */

#include <zephyr/ztest.h>
#include <zephyr/device.h>
#include <zephyr/devicetree.h>
#include <zephyr/sys/byteorder.h>
#include <drivers/dynamixel.h>

#include "fake_servo.h"

#define DXL_BUS_NODE   DT_NODELABEL(dxl_bus)
#define DXL_UART_NODE  DT_PARENT(DXL_BUS_NODE)
#define DXL_IFACE_NAME DEVICE_DT_NAME(DXL_BUS_NODE)

static const struct device *uart_dev = DEVICE_DT_GET(DXL_UART_NODE);

static struct fake_servo srv;
static int iface;

static void bring_up_default(void)
{
	struct dxl_iface_param p = {
		.rx_timeout = 50000,
		.serial = {.baud = 115200, .parity = UART_CFG_PARITY_NONE},
	};

	fake_servo_init(&srv, 1);
	fake_servo_attach(&srv, uart_dev);

	iface = dxl_iface_get_by_name(DXL_IFACE_NAME);
	zassert_true(iface >= 0, "iface lookup failed: %d", iface);
	zassert_ok(dxl_init(iface, p), "dxl_init failed");
}

static void protocol_before_each(void *fixture)
{
	ARG_UNUSED(fixture);
	bring_up_default();
}

static void protocol_after_each(void *fixture)
{
	ARG_UNUSED(fixture);
	dxl_disable(iface);
}

ZTEST_SUITE(dynamixel_protocol, NULL, NULL, protocol_before_each, protocol_after_each, NULL);

ZTEST(dynamixel_protocol, test_phase1_ping_request_bytes)
{
	zassert_ok(dxl_ping(iface, 1), "ping failed");

	zassert_equal(srv.last_tx[0], 0xFF, "header byte 0");
	zassert_equal(srv.last_tx[1], 0xFF, "header byte 1");
	zassert_equal(srv.last_tx[2], 0xFD, "header byte 2");
	zassert_equal(srv.last_tx[3], 0x00, "reserved");
	zassert_equal(srv.last_tx[4], 1, "id");
	zassert_equal(srv.last_tx[7], 0x01, "ping instruction");
	zassert_equal(srv.last_instruction, 0x01, "captured instruction");
}

ZTEST(dynamixel_protocol, test_timeout_returns_etimedout)
{
	uint32_t val32 = 0;
	int rc;

	srv.drop_response = true;

	rc = dxl_read_u32(iface, 1, PRESENT_POSITION, &val32);

	zassert_equal(rc, -ETIMEDOUT, "timeout must return -ETIMEDOUT, got %d", rc);
}

ZTEST(dynamixel_protocol, test_write_u8_round_trip)
{
	zassert_ok(dxl_write_u8(iface, 1, TORQUE_ENABLE, 1), "write failed");

	zassert_equal(srv.last_instruction, 0x03, "write instruction");
	zassert_equal(srv.last_addr, 64, "TORQUE_ENABLE addr");
	zassert_equal(srv.last_length, 1, "1-byte param");
	zassert_equal(fake_servo_get_u8(&srv, 64), 1, "RAM updated");
}

ZTEST(dynamixel_protocol, test_phase3_wrong_id_response_rejected)
{
	int rc;

	/* Force the fake to reply to the request even though its id (2) does not
	 * match the addressed id (1). The driver should detect the mismatched
	 * response id and discard it silently (no k_sem_give), so the
	 * wait_sem genuinely times out and the client sees -ETIMEDOUT.
	 */
	srv.id = 2;
	srv.answer_any_id = true;

	rc = dxl_ping(iface, 1);

	zassert_equal(rc, -ETIMEDOUT, "wrong-id reply should look like a timeout, got %d", rc);
}

ZTEST(dynamixel_protocol, test_read_u32_full_value)
{
	uint32_t val = 0;

	fake_servo_set_u32(&srv, 132 /* PRESENT_POSITION addr */, 0x12345678);

	zassert_ok(dxl_read_u32(iface, 1, PRESENT_POSITION, &val), "read failed");
	zassert_equal(val, 0x12345678, "got 0x%08x", val);
}

ZTEST(dynamixel_protocol, test_read_u16_full_value)
{
	uint16_t val = 0;

	fake_servo_set_u16(&srv, 100 /* GOAL_PWM addr */, 0xCAFE);

	zassert_ok(dxl_read_u16(iface, 1, GOAL_PWM, &val), "read failed");
	zassert_equal(val, 0xCAFE, "got 0x%04x", val);
}

ZTEST(dynamixel_protocol, test_read_u8_full_value)
{
	uint8_t val = 0;

	fake_servo_set_u8(&srv, 64 /* TORQUE_ENABLE addr */, 0xA5);

	zassert_ok(dxl_read_u8(iface, 1, TORQUE_ENABLE, &val), "read failed");
	zassert_equal(val, 0xA5, "got 0x%02x", val);
}

ZTEST(dynamixel_protocol, test_write_u32_round_trip)
{
	zassert_ok(dxl_write_u32(iface, 1, GOAL_POSITION, 0xDEADBEEF), "write failed");

	zassert_equal(srv.last_addr, 116, "GOAL_POSITION addr");
	zassert_equal(srv.last_length, 4, "4-byte param");
	zassert_equal(fake_servo_get_u32(&srv, 116), 0xDEADBEEF, "RAM");
}

ZTEST(dynamixel_protocol, test_width_mismatch_returns_einval)
{
	uint8_t val8;

	zassert_equal(dxl_read_u8(iface, 1, PRESENT_POSITION, &val8), -EINVAL,
		      "u8 read of 4-byte register");

	zassert_equal(dxl_write_u16(iface, 1, TORQUE_ENABLE, 0), -EINVAL,
		      "u16 write of 1-byte register");
}

ZTEST(dynamixel_protocol, test_invalid_register_returns_einval)
{
	uint32_t val32;

	zassert_equal(dxl_read_u32(iface, 1, (enum dxl_control)9999, &val32), -EINVAL,
		      "out-of-range register");
}

ZTEST(dynamixel_protocol, test_device_error_byte_returned_positive)
{
	uint32_t val = 0;
	int rc;

	srv.error_byte = DXL_ERR_DATA_RANGE;
	fake_servo_set_u32(&srv, 132, 0x11);

	rc = dxl_read_u32(iface, 1, PRESENT_POSITION, &val);

	zassert_equal(rc, DXL_ERR_DATA_RANGE,
		      "device error must be returned as positive enum, got %d", rc);
}

ZTEST(dynamixel_protocol, test_crc_error_returns_eio)
{
	uint32_t val = 0;
	int rc;

	srv.corrupt_crc = true;
	fake_servo_set_u32(&srv, 132 /* PRESENT_POSITION */, 0xFEEDFACE);

	rc = dxl_read_u32(iface, 1, PRESENT_POSITION, &val);

	zassert_equal(rc, -EIO, "corrupted CRC should return -EIO, got %d", rc);
}

/* A length field that disagrees with the bytes received used to size the copy
 * into rx_frame.data before the CRC was checked, overrunning it by up to 64 KiB.
 */
ZTEST(dynamixel_protocol, test_bad_length_field_returns_emsgsize)
{
	uint32_t val = 0;
	int rc;

	srv.corrupt_length = true;
	fake_servo_set_u32(&srv, 132 /* PRESENT_POSITION */, 0xFEEDFACE);

	rc = dxl_read_u32(iface, 1, PRESENT_POSITION, &val);

	zassert_equal(rc, -EMSGSIZE, "bad length field should return -EMSGSIZE, got %d", rc);
	zassert_equal(val, 0, "value must not be written on a bad frame");
}

ZTEST(dynamixel_protocol, test_write_u16_round_trip)
{
	zassert_ok(dxl_write_u16(iface, 1, GOAL_PWM, 0x0BEE), "write failed");

	zassert_equal(srv.last_instruction, 0x03, "write instruction");
	zassert_equal(srv.last_addr, 100, "GOAL_PWM addr");
	zassert_equal(srv.last_length, 2, "2-byte param");
	zassert_equal(fake_servo_get_u16(&srv, 100), 0x0BEE, "RAM updated");
}

ZTEST(dynamixel_protocol, test_reboot_request_bytes)
{
	zassert_ok(dxl_reboot(iface, 1), "reboot failed");

	zassert_equal(srv.last_instruction, 0x08, "reboot instruction");
	zassert_equal(srv.last_tx[4], 1, "id");
}

/* LE 0x00FDFFFF is FF FF FD 00: a header pattern inside the parameters, which
 * Protocol 2.0 escapes with an extra 0xFD.
 */
#define STUFFED_VALUE 0x00FDFFFFU

ZTEST(dynamixel_protocol, test_write_stuffs_header_pattern)
{
	zassert_ok(dxl_write_u32(iface, 1, GOAL_POSITION, STUFFED_VALUE), "write failed");

	/* ic + addr(2) + value(4) + stuffed 0xFD + crc(2) */
	zassert_equal(sys_get_le16(&srv.last_tx[5]), 10, "length must count the stuffed byte");
	zassert_mem_equal(&srv.last_tx[10], ((uint8_t[]){0xFF, 0xFF, 0xFD, 0xFD, 0x00}), 5,
			  "FF FF FD must be followed by a stuffed 0xFD");
	zassert_equal(fake_servo_get_u32(&srv, 116 /* GOAL_POSITION */), STUFFED_VALUE,
		      "servo must see the unstuffed value");
}

ZTEST(dynamixel_protocol, test_read_unstuffs_status)
{
	uint32_t val = 0;

	fake_servo_set_u32(&srv, 132 /* PRESENT_POSITION */, STUFFED_VALUE);

	zassert_ok(dxl_read_u32(iface, 1, PRESENT_POSITION, &val), "read failed");
	zassert_equal(val, STUFFED_VALUE, "stuffed status read back as 0x%08x", val);
}
```

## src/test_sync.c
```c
/*
 * Copyright (c) 2026 Richard Osterloh <richard.osterloh@gmail.com>
 *
 * SPDX-License-Identifier: Apache-2.0
 */

#include <zephyr/ztest.h>
#include <zephyr/device.h>
#include <zephyr/devicetree.h>
#include <drivers/dynamixel.h>

#include "fake_bus.h"

#define DXL_BUS_NODE   DT_NODELABEL(dxl_bus)
#define DXL_UART_NODE  DT_PARENT(DXL_BUS_NODE)
#define DXL_IFACE_NAME DEVICE_DT_NAME(DXL_BUS_NODE)

#define FAKE_BUS_RXWAIT_TO_US 10000U

static const struct device *uart_dev = DEVICE_DT_GET(DXL_UART_NODE);

static struct fake_bus bus;
static int iface;

static void sync_before_each(void *fixture)
{
	ARG_UNUSED(fixture);

	const uint8_t ids[] = {1, 2, 3, 4};
	struct dxl_iface_param p = {
		.rx_timeout = FAKE_BUS_RXWAIT_TO_US,
		.serial = {.baud = 115200, .parity = UART_CFG_PARITY_NONE},
	};

	fake_bus_init(&bus, ids, ARRAY_SIZE(ids));
	fake_bus_attach(&bus, uart_dev);

	iface = dxl_iface_get_by_name(DXL_IFACE_NAME);
	zassert_true(iface >= 0, "iface lookup failed: %d", iface);
	zassert_ok(dxl_init(iface, p), "dxl_init failed");
}

static void sync_after_each(void *fixture)
{
	ARG_UNUSED(fixture);
	dxl_disable(iface);
}

ZTEST_SUITE(dynamixel_sync, NULL, NULL, sync_before_each, sync_after_each, NULL);

ZTEST(dynamixel_sync, test_sync_write_u32_happy)
{
	const uint8_t ids[] = {1, 2, 3, 4};
	const uint32_t vals[] = {0x100, 0x200, 0x300, 0x400};

	zassert_ok(dxl_sync_write_u32(iface, GOAL_POSITION, ids, vals, ARRAY_SIZE(ids)),
		   "sync_write failed");

	/* SYNC_WRITE is fire-and-forget at the protocol layer. The emulated
	 * UART drains TX bytes through a worker thread, so we yield long
	 * enough for the bytes to reach the fake_bus dispatcher before
	 * checking register state. 2 ms is far more than the ~30-byte packet
	 * needs at 115200 baud (~2.6 ms wall) and far less than the test
	 * fixture's rxwait_to.
	 */
	k_sleep(K_MSEC(2));

	/* GOAL_POSITION is at addr 116 (4 bytes). Each servo should have its slice. */
	zassert_equal(fake_servo_get_u32(fake_bus_get(&bus, 1), 116), 0x100, "id 1");
	zassert_equal(fake_servo_get_u32(fake_bus_get(&bus, 2), 116), 0x200, "id 2");
	zassert_equal(fake_servo_get_u32(fake_bus_get(&bus, 3), 116), 0x300, "id 3");
	zassert_equal(fake_servo_get_u32(fake_bus_get(&bus, 4), 116), 0x400, "id 4");
}

ZTEST(dynamixel_sync, test_sync_write_u8_happy)
{
	const uint8_t ids[] = {1, 2, 3, 4};
	const uint8_t vals[] = {1, 0, 1, 0};

	zassert_ok(dxl_sync_write_u8(iface, TORQUE_ENABLE, ids, vals, ARRAY_SIZE(ids)),
		   "sync_write_u8 failed");

	/* SYNC_WRITE is fire-and-forget at the protocol layer; allow the
	 * emulated UART worker to drain before checking register state.
	 */
	k_sleep(K_MSEC(2));

	/* TORQUE_ENABLE is at addr 64 (1 byte). */
	zassert_equal(fake_servo_get_u8(fake_bus_get(&bus, 1), 64), 1, "id 1");
	zassert_equal(fake_servo_get_u8(fake_bus_get(&bus, 2), 64), 0, "id 2");
	zassert_equal(fake_servo_get_u8(fake_bus_get(&bus, 3), 64), 1, "id 3");
	zassert_equal(fake_servo_get_u8(fake_bus_get(&bus, 4), 64), 0, "id 4");
}

ZTEST(dynamixel_sync, test_sync_write_u16_happy)
{
	const uint8_t ids[] = {1, 2, 3, 4};
	const uint16_t vals[] = {0x0AAA, 0x0BBB, 0x0CCC, 0x0DDD};

	zassert_ok(dxl_sync_write_u16(iface, GOAL_PWM, ids, vals, ARRAY_SIZE(ids)),
		   "sync_write_u16 failed");

	k_sleep(K_MSEC(2));

	/* GOAL_PWM is at addr 100 (2 bytes). */
	zassert_equal(fake_servo_get_u16(fake_bus_get(&bus, 1), 100), 0x0AAA, "id 1");
	zassert_equal(fake_servo_get_u16(fake_bus_get(&bus, 2), 100), 0x0BBB, "id 2");
	zassert_equal(fake_servo_get_u16(fake_bus_get(&bus, 3), 100), 0x0CCC, "id 3");
	zassert_equal(fake_servo_get_u16(fake_bus_get(&bus, 4), 100), 0x0DDD, "id 4");
}

ZTEST(dynamixel_sync, test_sync_write_width_mismatch_returns_einval)
{
	const uint8_t ids[] = {1, 2};
	const uint8_t vals_u8[] = {0, 0};
	const uint16_t vals_u16[] = {0, 0};

	/* u8 helper called on a 4-byte register (GOAL_POSITION). */
	zassert_equal(dxl_sync_write_u8(iface, GOAL_POSITION, ids, vals_u8, 2), -EINVAL,
		      "u8 on 4-byte register");

	/* u16 helper called on a 1-byte register (TORQUE_ENABLE). */
	zassert_equal(dxl_sync_write_u16(iface, TORQUE_ENABLE, ids, vals_u16, 2), -EINVAL,
		      "u16 on 1-byte register");
}

ZTEST(dynamixel_sync, test_sync_write_validation_einval)
{
	const uint8_t ids[] = {1, 2};
	const uint32_t vals[] = {0, 0};

	/* n = 0 is invalid. */
	zassert_equal(dxl_sync_write_u32(iface, GOAL_POSITION, ids, vals, 0), -EINVAL, "n=0");

	/* NULL ids. */
	zassert_equal(dxl_sync_write_u32(iface, GOAL_POSITION, NULL, vals, 2), -EINVAL, "NULL ids");

	/* NULL vals. */
	zassert_equal(dxl_sync_write_u32(iface, GOAL_POSITION, ids, NULL, 2), -EINVAL, "NULL vals");

	/* Out-of-range item. */
	zassert_equal(dxl_sync_write_u32(iface, (enum dxl_control)9999, ids, vals, 2), -EINVAL,
		      "bad item");
}

ZTEST(dynamixel_sync, test_sync_write_enospc_when_oversized)
{
	/* CONFIG_DYNAMIXEL_BUFFER_SIZE defaults to 256. SYNC_WRITE u32 with N
	 * servos needs 14 + N*5 bytes. N=49 -> 259 > 256. Use a fabricated
	 * over-large id list (the dispatcher won't actually fire — call returns
	 * -ENOSPC before TX).
	 */
	uint8_t ids[64];
	uint32_t vals[64];
	for (size_t i = 0; i < ARRAY_SIZE(ids); i++) {
		ids[i] = (uint8_t)(i + 1);
		vals[i] = 0;
	}

	zassert_equal(dxl_sync_write_u32(iface, GOAL_POSITION, ids, vals, 64), -ENOSPC,
		      "oversized request must return -ENOSPC");
}

ZTEST(dynamixel_sync, test_sync_read_u32_happy)
{
	const uint8_t ids[] = {1, 2, 3, 4};
	uint32_t vals[4] = {0};
	int errs[4] = {-1, -1, -1, -1};

	/* PRESENT_POSITION at addr 132 (4 bytes). */
	fake_bus_set_u32(&bus, 1, 132, 0x11111111);
	fake_bus_set_u32(&bus, 2, 132, 0x22222222);
	fake_bus_set_u32(&bus, 3, 132, 0x33333333);
	fake_bus_set_u32(&bus, 4, 132, 0x44444444);

	int rc = dxl_sync_read_u32(iface, PRESENT_POSITION, ids, vals, errs, ARRAY_SIZE(ids));
	zassert_ok(rc, "sync_read returned %d", rc);

	zassert_equal(vals[0], 0x11111111, "vals[0]");
	zassert_equal(vals[1], 0x22222222, "vals[1]");
	zassert_equal(vals[2], 0x33333333, "vals[2]");
	zassert_equal(vals[3], 0x44444444, "vals[3]");
	zassert_equal(errs[0], 0, "errs[0]");
	zassert_equal(errs[1], 0, "errs[1]");
	zassert_equal(errs[2], 0, "errs[2]");
	zassert_equal(errs[3], 0, "errs[3]");
}

ZTEST(dynamixel_sync, test_sync_read_u8_happy)
{
	const uint8_t ids[] = {1, 2, 3, 4};
	uint8_t vals[4] = {0};
	int errs[4] = {-1, -1, -1, -1};

	/* TORQUE_ENABLE at addr 64 (1 byte). */
	fake_bus_set_u8(&bus, 1, 64, 1);
	fake_bus_set_u8(&bus, 2, 64, 0);
	fake_bus_set_u8(&bus, 3, 64, 1);
	fake_bus_set_u8(&bus, 4, 64, 0);

	zassert_ok(dxl_sync_read_u8(iface, TORQUE_ENABLE, ids, vals, errs, ARRAY_SIZE(ids)),
		   "sync_read_u8 failed");
	zassert_equal(vals[0], 1, "");
	zassert_equal(vals[1], 0, "");
	zassert_equal(vals[2], 1, "");
	zassert_equal(vals[3], 0, "");
}

ZTEST(dynamixel_sync, test_sync_read_u16_happy)
{
	const uint8_t ids[] = {1, 2, 3, 4};
	uint16_t vals[4] = {0};
	int errs[4] = {-1, -1, -1, -1};

	/* GOAL_PWM at addr 100 (2 bytes). */
	fake_bus_set_u16(&bus, 1, 100, 0x1111);
	fake_bus_set_u16(&bus, 2, 100, 0x2222);
	fake_bus_set_u16(&bus, 3, 100, 0x3333);
	fake_bus_set_u16(&bus, 4, 100, 0x4444);

	zassert_ok(dxl_sync_read_u16(iface, GOAL_PWM, ids, vals, errs, ARRAY_SIZE(ids)),
		   "sync_read_u16 failed");
	zassert_equal(vals[0], 0x1111, "");
	zassert_equal(vals[1], 0x2222, "");
	zassert_equal(vals[2], 0x3333, "");
	zassert_equal(vals[3], 0x4444, "");
}

ZTEST(dynamixel_sync, test_sync_read_partial_drop)
{
	const uint8_t ids[] = {1, 2, 3, 4};
	uint32_t vals[4] = {0xFEEDFEED, 0xFEEDFEED, 0xFEEDFEED, 0xFEEDFEED};
	int errs[4] = {0};

	fake_bus_set_u32(&bus, 1, 132, 0xAAAA0001);
	fake_bus_set_u32(&bus, 2, 132, 0xAAAA0002);
	fake_bus_set_u32(&bus, 3, 132, 0xAAAA0003);
	fake_bus_set_u32(&bus, 4, 132, 0xAAAA0004);

	/* Servo 3 silently fails to respond. Servos 1/2/4 reply normally. */
	fake_bus_get(&bus, 3)->drop_response = true;

	int rc = dxl_sync_read_u32(iface, PRESENT_POSITION, ids, vals, errs, ARRAY_SIZE(ids));

	zassert_equal(rc, -EIO, "summary must be -EIO when any slot fails, got %d", rc);
	zassert_equal(errs[0], 0, "errs[0]");
	zassert_equal(errs[1], 0, "errs[1]");
	zassert_equal(errs[2], -ETIMEDOUT, "errs[2] expected -ETIMEDOUT, got %d", errs[2]);
	zassert_equal(errs[3], 0, "errs[3]");

	zassert_equal(vals[0], 0xAAAA0001, "vals[0]");
	zassert_equal(vals[1], 0xAAAA0002, "vals[1]");
	zassert_equal(vals[2], 0xFEEDFEED, "vals[2] must be untouched on drop");
	zassert_equal(vals[3], 0xAAAA0004, "vals[3]");
}

ZTEST(dynamixel_sync, test_sync_read_device_error_byte)
{
	const uint8_t ids[] = {1, 2, 3, 4};
	uint32_t vals[4] = {0};
	int errs[4] = {0};

	fake_bus_set_u32(&bus, 1, 132, 0xAAAA0001);
	fake_bus_set_u32(&bus, 2, 132, 0xAAAA0002);
	fake_bus_set_u32(&bus, 3, 132, 0xAAAA0003);
	fake_bus_set_u32(&bus, 4, 132, 0xAAAA0004);

	/* Servo 2 returns a device-error byte. The driver treats it as a
	 * positive return code in errs[1]; vals[1] is left untouched.
	 */
	fake_bus_get(&bus, 2)->error_byte = DXL_ERR_DATA_RANGE;

	int rc = dxl_sync_read_u32(iface, PRESENT_POSITION, ids, vals, errs, ARRAY_SIZE(ids));

	zassert_equal(rc, -EIO, "summary must be -EIO");
	zassert_equal(errs[0], 0, "errs[0]");
	zassert_equal(errs[1], DXL_ERR_DATA_RANGE, "errs[1] must be device-error byte, got %d",
		      errs[1]);
	zassert_equal(errs[2], 0, "errs[2]");
	zassert_equal(errs[3], 0, "errs[3]");
	zassert_equal(vals[1], 0, "vals[1] must be untouched on dev err");
	zassert_equal(vals[0], 0xAAAA0001, "vals[0]");
	zassert_equal(vals[2], 0xAAAA0003, "vals[2]");
	zassert_equal(vals[3], 0xAAAA0004, "vals[3]");
}

ZTEST(dynamixel_sync, test_sync_read_wrong_id_reply_is_timeout)
{
	const uint8_t ids[] = {1, 2, 3, 4};
	uint32_t vals[4] = {0};
	int errs[4] = {0};

	fake_bus_set_u32(&bus, 1, 132, 0xAAAA0001);
	fake_bus_set_u32(&bus, 2, 132, 0xAAAA0002);
	fake_bus_set_u32(&bus, 3, 132, 0xAAAA0003);
	fake_bus_set_u32(&bus, 4, 132, 0xAAAA0004);

	/* For slot 2 (id=3 expected), make servo 3 reply with a different id (5).
	 * The driver discards the wrong-id frame in dxl_rx_handler (-EBADMSG)
	 * and silently re-enables RX. With no other reply incoming, the slot
	 * times out as -ETIMEDOUT. Subsequent slots still proceed.
	 */
	struct fake_servo *s3 = fake_bus_get(&bus, 3);
	s3->id = 5; /* respond as id 5 even though id 3 was requested */
	s3->answer_any_id = true;

	int rc = dxl_sync_read_u32(iface, PRESENT_POSITION, ids, vals, errs, ARRAY_SIZE(ids));

	zassert_equal(rc, -EIO, "summary must be -EIO");
	zassert_equal(errs[0], 0, "errs[0]");
	zassert_equal(errs[1], 0, "errs[1]");
	zassert_equal(errs[2], -ETIMEDOUT, "errs[2] expected -ETIMEDOUT for wrong-id, got %d",
		      errs[2]);
	zassert_equal(errs[3], 0, "errs[3]");
}

ZTEST(dynamixel_sync, test_sync_read_errs_null_collapses_to_eio)
{
	const uint8_t ids[] = {1, 2, 3, 4};
	uint32_t vals[4] = {0xFEEDFEED, 0xFEEDFEED, 0xFEEDFEED, 0xFEEDFEED};

	fake_bus_set_u32(&bus, 1, 132, 0xAAAA0001);
	fake_bus_set_u32(&bus, 2, 132, 0xAAAA0002);
	fake_bus_set_u32(&bus, 3, 132, 0xAAAA0003);
	fake_bus_set_u32(&bus, 4, 132, 0xAAAA0004);

	fake_bus_get(&bus, 3)->drop_response = true;

	int rc = dxl_sync_read_u32(iface, PRESENT_POSITION, ids, vals,
				   /*errs=*/NULL, ARRAY_SIZE(ids));

	zassert_equal(rc, -EIO, "errs=NULL must still collapse failures to -EIO, got %d", rc);
	zassert_equal(vals[0], 0xAAAA0001, "vals[0]");
	zassert_equal(vals[1], 0xAAAA0002, "vals[1]");
	zassert_equal(vals[2], 0xFEEDFEED, "vals[2] must be untouched even when errs is NULL");
	zassert_equal(vals[3], 0xAAAA0004, "vals[3]");
}

ZTEST(dynamixel_sync, test_sync_read_validation_einval)
{
	const uint8_t ids[] = {1, 2};
	uint32_t vals[2] = {0};

	zassert_equal(dxl_sync_read_u32(iface, PRESENT_POSITION, ids, vals, NULL, 0), -EINVAL,
		      "n=0");
	zassert_equal(dxl_sync_read_u32(iface, PRESENT_POSITION, NULL, vals, NULL, 2), -EINVAL,
		      "NULL ids");
	zassert_equal(dxl_sync_read_u32(iface, PRESENT_POSITION, ids, NULL, NULL, 2), -EINVAL,
		      "NULL vals");
	zassert_equal(dxl_sync_read_u32(iface, (enum dxl_control)9999, ids, vals, NULL, 2), -EINVAL,
		      "bad item");

	uint8_t vals_u8[2] = {0};
	zassert_equal(dxl_sync_read_u8(iface, PRESENT_POSITION, ids, vals_u8, NULL, 2), -EINVAL,
		      "u8 on 4-byte register");
}

ZTEST(dynamixel_sync, test_sync_read_enospc_when_oversized)
{
	uint8_t ids[256];
	uint32_t vals[256];
	for (size_t i = 0; i < ARRAY_SIZE(ids); i++) {
		ids[i] = (uint8_t)((i % 250) + 1);
		vals[i] = 0;
	}

	/* SYNC_READ packet is 14 + N bytes. For N=256 -> 270 > 256 default. */
	zassert_equal(dxl_sync_read_u32(iface, PRESENT_POSITION, ids, vals, NULL, 256), -ENOSPC,
		      "oversized SYNC_READ must return -ENOSPC");
}
```
